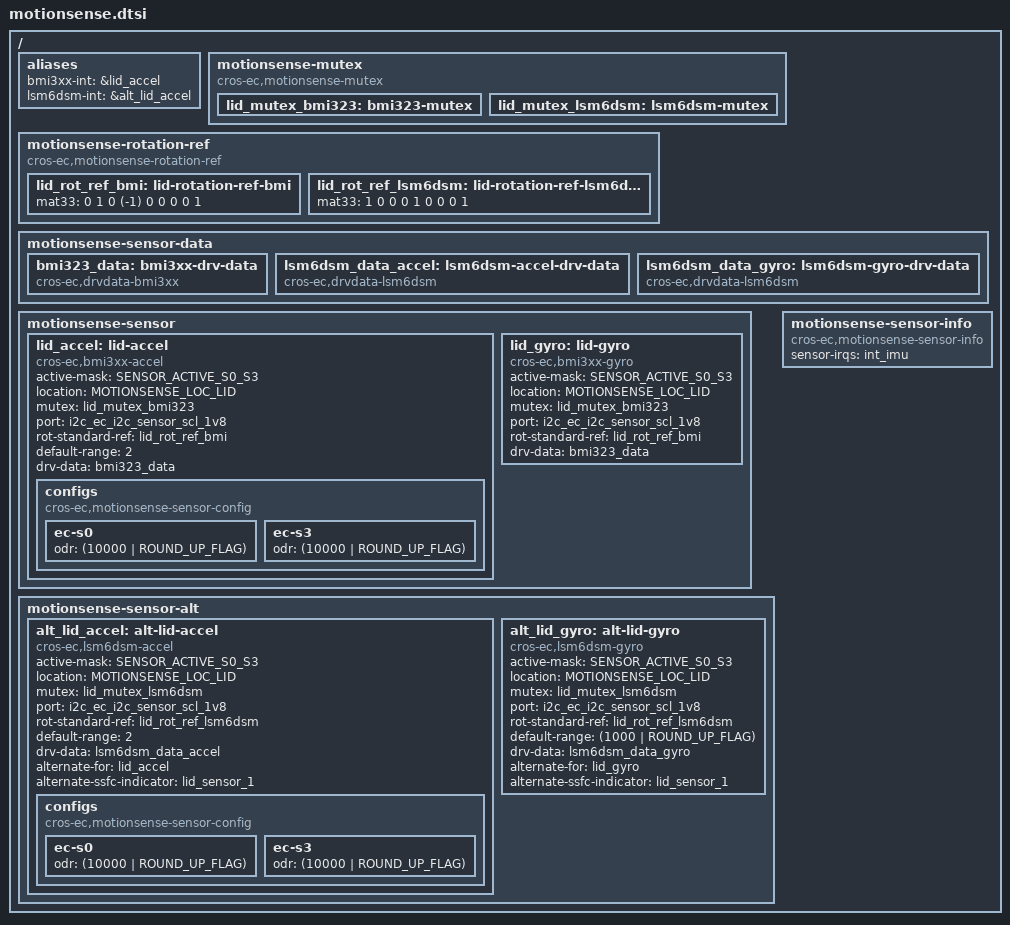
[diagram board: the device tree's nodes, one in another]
/* Copyright 2025 The ChromiumOS Authors
 * Use of this source code is governed by a BSD-style license that can be
 * found in the LICENSE file.
 */

#include <dt-bindings/motionsense/utils.h>

/ {
	aliases {
		/*
		 * motion sense's <>_INT_EVENT is handled
		 * by alias. Using the alias, each driver creates
		 * its own <>_INT_EVENT.
		 */
		bmi3xx-int = &lid_accel;
		lsm6dsm-int = &alt_lid_accel;
	};

	motionsense-mutex {
		compatible = "cros-ec,motionsense-mutex";
		lid_mutex_bmi323: bmi323-mutex {
		};
		lid_mutex_lsm6dsm: lsm6dsm-mutex {
		};
	};

	/* Rotation matrix used by drivers. */
	motionsense-rotation-ref {
		compatible = "cros-ec,motionsense-rotation-ref";
		lid_rot_ref_bmi: lid-rotation-ref-bmi {
			mat33 = <0 1 0
				 (-1) 0 0
				 0 0 1>;
		};
		lid_rot_ref_lsm6dsm: lid-rotation-ref-lsm6dsm {
			mat33 = <1 0 0
				 0 1 0
				 0 0 1>;
		};
	};

	motionsense-sensor-data {
		bmi323_data: bmi3xx-drv-data {
			compatible = "cros-ec,drvdata-bmi3xx";
			status = "okay";
		};
		lsm6dsm_data_accel: lsm6dsm-accel-drv-data {
			compatible = "cros-ec,drvdata-lsm6dsm";
			status = "okay";
		};
		lsm6dsm_data_gyro: lsm6dsm-gyro-drv-data {
			compatible = "cros-ec,drvdata-lsm6dsm";
			status = "okay";
		};
	};

	motionsense-sensor {
		lid_accel: lid-accel {
			compatible = "cros-ec,bmi3xx-accel";
			status = "okay";

			active-mask = "SENSOR_ACTIVE_S0_S3";
			location = "MOTIONSENSE_LOC_LID";
			mutex = <&lid_mutex_bmi323>;
			port = <&i2c_ec_i2c_sensor_scl_1v8>;
			rot-standard-ref = <&lid_rot_ref_bmi>;
			default-range = <2>;
			drv-data = <&bmi323_data>;
			configs {
				compatible =
					"cros-ec,motionsense-sensor-config";
				ec-s0 {
					odr = <(10000 | ROUND_UP_FLAG)>;
				};
				ec-s3 {
					odr = <(10000 | ROUND_UP_FLAG)>;
				};
			};
		};

		lid_gyro: lid-gyro {
			compatible = "cros-ec,bmi3xx-gyro";
			status = "okay";

			active-mask = "SENSOR_ACTIVE_S0_S3";
			location = "MOTIONSENSE_LOC_LID";
			mutex = <&lid_mutex_bmi323>;
			port = <&i2c_ec_i2c_sensor_scl_1v8>;
			rot-standard-ref = <&lid_rot_ref_bmi>;
			drv-data = <&bmi323_data>;
		};
	};

	motionsense-sensor-alt {
		alt_lid_accel: alt-lid-accel {
			compatible = "cros-ec,lsm6dsm-accel";
			status = "okay";

			active-mask = "SENSOR_ACTIVE_S0_S3";
			location = "MOTIONSENSE_LOC_LID";
			mutex = <&lid_mutex_lsm6dsm>;
			port = <&i2c_ec_i2c_sensor_scl_1v8>;
			rot-standard-ref = <&lid_rot_ref_lsm6dsm>;
			default-range = <2>;
			drv-data = <&lsm6dsm_data_accel>;
			alternate-for = <&lid_accel>;
			alternate-ssfc-indicator = <&lid_sensor_1>;
			configs {
				compatible =
					"cros-ec,motionsense-sensor-config";
				ec-s0 {
					odr = <(10000 | ROUND_UP_FLAG)>;
				};
				ec-s3 {
					odr = <(10000 | ROUND_UP_FLAG)>;
				};
			};
		};

		alt_lid_gyro: alt-lid-gyro {
			compatible = "cros-ec,lsm6dsm-gyro";
			status = "okay";

			active-mask = "SENSOR_ACTIVE_S0_S3";
			location = "MOTIONSENSE_LOC_LID";
			mutex = <&lid_mutex_lsm6dsm>;
			port = <&i2c_ec_i2c_sensor_scl_1v8>;
			rot-standard-ref = <&lid_rot_ref_lsm6dsm>;
			default-range = <(1000 | ROUND_UP_FLAG)>; /* dps */
			drv-data = <&lsm6dsm_data_gyro>;
			alternate-for = <&lid_gyro>;
			alternate-ssfc-indicator = <&lid_sensor_1>;
		};
	};

	/* High level description info */
	motionsense-sensor-info {
		compatible = "cros-ec,motionsense-sensor-info";
		/*
		 * List of GPIO interrupts that have to be enabled at initial
		 * stage.
		 */
		sensor-irqs = <&int_imu>;
	};
};
